# RP2040 register map
Vendor: Raspberry Pi; File version: 0.1
CPU: CM0PLUS r0p1, little endian, MPU, no FPU, VTOR, 2 interrupt priority bits, 26 interrupts
Registers are 32-bit, read-write, reset 0x0 unless marked. A register's access mark holds for its fields unless they carry their own. Offsets are from the block's base; [hi:lo] are bit positions; {n}, {i} and the like mark numbered series.

## USBCTRL_DPRAM — DPRAM layout for USB device.
Base 0x50100000
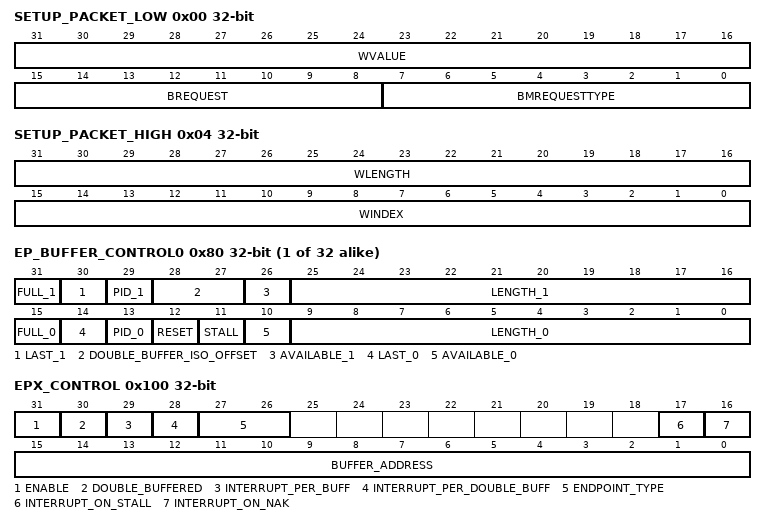
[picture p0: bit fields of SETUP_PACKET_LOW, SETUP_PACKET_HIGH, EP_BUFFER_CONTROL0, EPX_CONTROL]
0x00 SETUP_PACKET_LOW — Bytes 0-3 of the SETUP packet from the host.
  [31:16] WVALUE, [15:8] BREQUEST, [7:0] BMREQUESTTYPE
0x04 SETUP_PACKET_HIGH — Bytes 4-7 of the setup packet from the host.
  [31:16] WLENGTH, [15:0] WINDEX
{0x8+4i} EP_CONTROL{i} (i=0..29) access not given
  [31] ENABLE rw — Enable this endpoint. The device will not reply to any packets for this endpoint if this bit is not set.
  [30] DOUBLE_BUFFERED rw — This endpoint is double buffered.
  [29] INTERRUPT_PER_BUFF rw — Trigger an interrupt each time a buffer is done.
  [28] INTERRUPT_PER_DOUBLE_BUFF rw — Trigger an interrupt each time both buffers are done. Only valid in double buffered mode.
  [27:26] ENDPOINT_TYPE rw
    0=Control; 1=Isochronous; 2=Bulk; 3=Interrupt
  [17] INTERRUPT_ON_STALL rw — Trigger an interrupt if a STALL is sent. Intended for debug only.
  [16] INTERRUPT_ON_NAK rw — Trigger an interrupt if a NAK is sent. Intended for debug only.
  [25:16] HOST_POLL_INTERVAL — The interval the host controller should poll this endpoint. Only applicable for interrupt endpoints. Specified in ms - 1. For example: a value of 9 would poll the endpoint every 10ms.
  [15:0] BUFFER_ADDRESS rw — 64 byte aligned buffer address for this EP (bits 0-5 are ignored). Relative to the start of the DPRAM.
{0x80+4i} EP_BUFFER_CONTROL{i} (i=0..31)
  [31] FULL_1 — Buffer 1 is full. For an IN transfer (TX to the host) the bit is set to indicate the data is valid. For an OUT transfer (RX from the host) this bit should be left as a 0. The host will set it when it has filled the buffer with data.
  [30] LAST_1 — Buffer 1 is the last buffer of the transfer.
  [29] PID_1 — The data pid of buffer 1.
  [28:27] DOUBLE_BUFFER_ISO_OFFSET — The number of bytes buffer 1 is offset from buffer 0 in Isochronous mode. Only valid in double buffered mode for an Isochronous endpoint. For a non Isochronous endpoint the offset is always 64 bytes.
    0=128; 1=256; 2=512; 3=1024
  [26] AVAILABLE_1 — Buffer 1 is available. This bit is set to indicate the buffer can be used by the controller. The controller clears the available bit when writing the status back.
  [25:16] LENGTH_1 — The length of the data in buffer 1.
  [15] FULL_0 — Buffer 0 is full. For an IN transfer (TX to the host) the bit is set to indicate the data is valid. For an OUT transfer (RX from the host) this bit should be left as a 0. The host will set it when it has filled the buffer with data.
  [14] LAST_0 — Buffer 0 is the last buffer of the transfer.
  [13] PID_0 — The data pid of buffer 0.
  [12] RESET — Reset the buffer selector to buffer 0.
  [11] STALL — Reply with a stall (valid for both buffers).
  [10] AVAILABLE_0 — Buffer 0 is available. This bit is set to indicate the buffer can be used by the controller. The controller clears the available bit when writing the status back.
  [9:0] LENGTH_0 — The length of the data in buffer 0.
0x100 EPX_CONTROL — EPx Control (Host-mode only!)
  [31] ENABLE — Enable this endpoint. The device will not reply to any packets for this endpoint if this bit is not set.
  [30] DOUBLE_BUFFERED — This endpoint is double buffered.
  [29] INTERRUPT_PER_BUFF — Trigger an interrupt each time a buffer is done.
  [28] INTERRUPT_PER_DOUBLE_BUFF — Trigger an interrupt each time both buffers are done. Only valid in double buffered mode.
  [27:26] ENDPOINT_TYPE
    0=Control; 1=Isochronous; 2=Bulk; 3=Interrupt
  [17] INTERRUPT_ON_STALL — Trigger an interrupt if a STALL is sent. Intended for debug only.
  [16] INTERRUPT_ON_NAK — Trigger an interrupt if a NAK is sent. Intended for debug only.
  [15:0] BUFFER_ADDRESS — 64 byte aligned buffer address for this EP (bits 0-5 are ignored). Relative to the start of the DPRAM.
